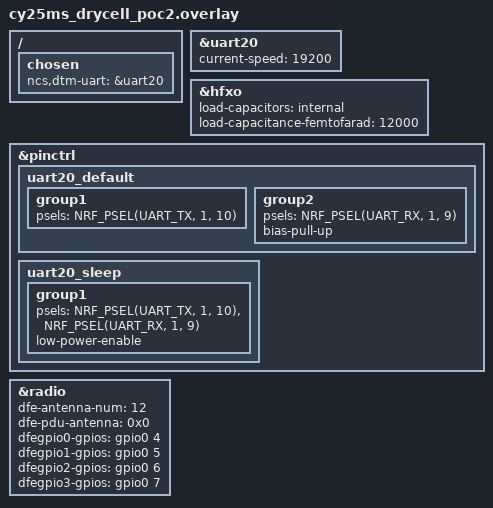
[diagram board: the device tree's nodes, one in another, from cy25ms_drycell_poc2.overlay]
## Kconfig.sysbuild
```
#
# Copyright (c) 2024 Nordic Semiconductor
#
# SPDX-License-Identifier: LicenseRef-Nordic-5-Clause
#

choice APPCORE
	default APPCORE_REMOTE_HCI if DTM_TRANSPORT_HCI
	default APPCORE_REMOTE_SHELL if SOC_NRF5340_CPUNET
	depends on SUPPORT_APPCORE

config APPCORE_REMOTE_HCI
	bool "remote_hci"
	depends on SOC_NRF5340_CPUNET
	help
	  Include remote_hci as the appcore image to use

endchoice

config APPCORE_IMAGE_NAME
	default "remote_hci" if APPCORE_REMOTE_HCI

config APPCORE_IMAGE_PATH
	default "${ZEPHYR_NRF_MODULE_DIR}/samples/bluetooth/direct_test_mode/remote_hci" if APPCORE_REMOTE_HCI

choice DTM_TRANSPORT
	default DTM_TRANSPORT_TWOWIRE
	prompt "Transport layer to use with DTM"
	help
	  Transport interface to use with the DTM.

config DTM_TRANSPORT_TWOWIRE
	bool "DTM over 2-wire UART"
	help
	  Use the 2-wire transport interface as the DTM transport layer.

config DTM_TRANSPORT_HCI
	bool "DTM over HCI UART [EXPERIMENTAL]"
	select EXPERIMENTAL
	help
	  Use the HCI UART transport interface as the DTM transport layer.

endchoice # DTM_TRANSPORT

config DTM_NO_DFE
	bool "Disable direction finding"
	help
	  Disable direction finding feature.

source "${ZEPHYR_BASE}/share/sysbuild/Kconfig"
```

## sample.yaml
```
sample:
  description: Bluetooth Low Energy Direct Test Mode sample
  name: Bluetooth LE Direct Test Mode
tests:
  sample.bluetooth.direct_test_mode:
    sysbuild: true
    build_only: true
    integration_platforms:
      - nrf5340dk/nrf5340/cpunet
      - nrf21540dk/nrf52840
      - nrf52840dk/nrf52840
      - nrf54l15dk/nrf54l05/cpuapp
      - nrf54l15dk/nrf54l10/cpuapp
      - nrf54l15dk/nrf54l15/cpuapp
      - nrf54h20dk/nrf54h20/cpurad
    platform_allow: nrf5340dk/nrf5340/cpunet nrf21540dk/nrf52840 nrf52840dk/nrf52840
                    nrf54l15dk/nrf54l05/cpuapp nrf54l15dk/nrf54l10/cpuapp
                    nrf54l15dk/nrf54l15/cpuapp nrf54h20dk/nrf54h20/cpurad
    tags: bluetooth ci_build sysbuild
  sample.bluetooth.direct_test_mode.hci:
    sysbuild: true
    build_only: true
    extra_args: FILE_SUFFIX=hci
    integration_platforms:
      - nrf5340dk/nrf5340/cpunet
      - nrf21540dk/nrf52840
      - nrf52840dk/nrf52840
      - nrf54l15dk/nrf54l15/cpuapp
      - nrf54h20dk/nrf54h20/cpurad
    platform_allow: nrf5340dk/nrf5340/cpunet nrf21540dk/nrf52840 nrf52840dk/nrf52840
                    nrf54l15dk/nrf54l15/cpuapp nrf54h20dk/nrf54h20/cpurad
    tags: bluetooth ci_build sysbuild
  sample.bluetooth.direct_test_mode.nrf5340_nrf21540:
    sysbuild: true
    build_only: true
    extra_args: SHIELD=nrf21540ek
    integration_platforms:
      - nrf5340dk/nrf5340/cpunet
    platform_allow: nrf5340dk/nrf5340/cpunet
    tags: bluetooth ci_build sysbuild
  sample.bluetooth.direct_test_mode.nrf5340_usb:
    sysbuild: true
    build_only: true
    extra_args: FILE_SUFFIX=usb
    integration_platforms:
      - nrf5340dk/nrf5340/cpunet
    platform_allow: nrf5340dk/nrf5340/cpunet
    tags: bluetooth ci_build sysbuild
  sample.bluetooth.direct_test_mode.nrf5340_nrf21540_usb:
    sysbuild: true
    build_only: true
    extra_args: SHIELD=nrf21540ek FILE_SUFFIX=usb
    integration_platforms:
      - nrf5340dk/nrf5340/cpunet
    platform_allow: nrf5340dk/nrf5340/cpunet
    tags: bluetooth ci_build sysbuild
  sample.bluetooth.direct_test_mode.nrf5340_nrf21540.no_automatic_power:
    sysbuild: true
    build_only: true
    extra_args: SHIELD=nrf21540ek
    extra_configs:
      - CONFIG_DTM_POWER_CONTROL_AUTOMATIC=n
    integration_platforms:
      - nrf5340dk/nrf5340/cpunet
    platform_allow: nrf5340dk/nrf5340/cpunet
    tags: bluetooth ci_build sysbuild
  sample.bluetooth.direct_test_mode.nrf5340_no_dfe:
    sysbuild: true
    build_only: true
    extra_args: DSB_CONFIG_DTM_NO_DFE=y
    integration_platforms:
      - nrf5340dk/nrf5340/cpunet
    platform_allow: nrf5340dk/nrf5340/cpunet
    tags: bluetooth ci_build sysbuild
```

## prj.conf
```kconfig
#
# Copyright (c) 2020 Nordic Semiconductor
#
# SPDX-License-Identifier: LicenseRef-Nordic-5-Clause
#

# Configure assertions
CONFIG_ASSERT=y
CONFIG_ASSERT_NO_COND_INFO=y
CONFIG_ASSERT_NO_MSG_INFO=y

CONFIG_HW_STACK_PROTECTION=y

CONFIG_CONSOLE=n
CONFIG_UART_CONSOLE=n

CONFIG_LOG=y
CONFIG_LOG_PRINTK=y
CONFIG_USE_SEGGER_RTT=y
CONFIG_LOG_BACKEND_RTT=y

# Use necessary peripherals
CONFIG_NRFX_TIMER0=y
CONFIG_NRFX_TIMER1=y
CONFIG_NRFX_TIMER2=y
CONFIG_CLOCK_CONTROL=y

CONFIG_FEM_AL_LIB=y
```

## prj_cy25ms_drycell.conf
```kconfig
#
# Copyright (c) 2020 Nordic Semiconductor
#
# SPDX-License-Identifier: LicenseRef-Nordic-5-Clause
#

# Configure assertions
CONFIG_ASSERT=y
CONFIG_ASSERT_NO_COND_INFO=y
CONFIG_ASSERT_NO_MSG_INFO=y

CONFIG_HW_STACK_PROTECTION=y

CONFIG_CONSOLE=n
CONFIG_UART_CONSOLE=n

CONFIG_LOG=y
CONFIG_LOG_PRINTK=y
CONFIG_USE_SEGGER_RTT=y
CONFIG_LOG_BACKEND_RTT=y

# Use necessary peripherals
CONFIG_NRFX_TIMER0=y
CONFIG_NRFX_TIMER1=y
CONFIG_NRFX_TIMER2=y

CONFIG_FEM_AL_LIB=y

# Disable the unsupported driver
CONFIG_NRFX_TIMER0=n
CONFIG_NRFX_TIMER1=n
CONFIG_NRFX_TIMER2=n

# Use necessary peripherals
CONFIG_NRFX_TIMER20=y
CONFIG_NRFX_TIMER10=y
CONFIG_NRFX_DPPI=y

#CONFIG_SOC_SERIES_NRF54LX=y

CONFIG_CLOCK_CONTROL_NRF_K32SRC_RC=y
CONFIG_CLOCK_CONTROL_NRF_K32SRC_XTAL=n
CONFIG_CLOCK_CONTROL_NRF_K32SRC_500PPM=y
```

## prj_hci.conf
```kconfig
#
# Copyright (c) 2020 Nordic Semiconductor
#
# SPDX-License-Identifier: LicenseRef-Nordic-5-Clause
#

# Configure assertions
CONFIG_ASSERT=y
CONFIG_ASSERT_NO_COND_INFO=y
CONFIG_ASSERT_NO_MSG_INFO=y

CONFIG_HW_STACK_PROTECTION=y

CONFIG_CONSOLE=n
CONFIG_UART_CONSOLE=n

CONFIG_LOG=y
CONFIG_LOG_PRINTK=y
CONFIG_USE_SEGGER_RTT=y
CONFIG_LOG_BACKEND_RTT=y

# Use necessary peripherals
CONFIG_NRFX_TIMER0=y
CONFIG_NRFX_TIMER1=y
CONFIG_NRFX_TIMER2=y
CONFIG_CLOCK_CONTROL=y

CONFIG_FEM_AL_LIB=y

CONFIG_DTM_TRANSPORT_HCI=y
CONFIG_NET_BUF=y
CONFIG_UART_ASYNC_API=y
```

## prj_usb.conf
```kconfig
#
# Copyright (c) 2020 Nordic Semiconductor
#
# SPDX-License-Identifier: LicenseRef-Nordic-5-Clause
#

# Configure assertions
CONFIG_ASSERT=y
CONFIG_ASSERT_NO_COND_INFO=y
CONFIG_ASSERT_NO_MSG_INFO=y

CONFIG_HW_STACK_PROTECTION=y

CONFIG_CONSOLE=n
CONFIG_UART_CONSOLE=n

CONFIG_LOG=y
CONFIG_LOG_PRINTK=y
CONFIG_USE_SEGGER_RTT=y
CONFIG_LOG_BACKEND_RTT=y

# Use necessary peripherals
CONFIG_NRFX_TIMER0=y
CONFIG_NRFX_TIMER1=y
CONFIG_NRFX_TIMER2=y
CONFIG_CLOCK_CONTROL=y

CONFIG_FEM_AL_LIB=y

CONFIG_DTM_USB=y
```

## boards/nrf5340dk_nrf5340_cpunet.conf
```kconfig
#
# Copyright (c) 2021 Nordic Semiconductor
#
# SPDX-License-Identifier: LicenseRef-Nordic-5-Clause
#

CONFIG_IPC_UART=y
CONFIG_IPC_SERVICE=y
CONFIG_IPC_SERVICE_BACKEND_RPMSG=y
CONFIG_MBOX=y

CONFIG_NRFX_GPPI=y

CONFIG_HEAP_MEM_POOL_SIZE=4096
```

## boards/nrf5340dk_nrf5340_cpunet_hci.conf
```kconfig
#
# Copyright (c) 2021 Nordic Semiconductor
#
# SPDX-License-Identifier: LicenseRef-Nordic-5-Clause
#

CONFIG_IPC_SERVICE=y
CONFIG_IPC_SERVICE_BACKEND_RPMSG=y
CONFIG_MBOX=y

CONFIG_NRFX_GPPI=y

CONFIG_HEAP_MEM_POOL_SIZE=4096

CONFIG_NRF_RPC=y
CONFIG_NRF_RPC_CBOR=y

CONFIG_NET_BUF=y
```

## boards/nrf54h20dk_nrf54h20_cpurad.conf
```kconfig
#
# Copyright (c) 2024 Nordic Semiconductor
#
# SPDX-License-Identifier: LicenseRef-Nordic-5-Clause
#

# Disable the unsupported driver
CONFIG_NRFX_TIMER0=n
CONFIG_NRFX_TIMER1=n
CONFIG_NRFX_TIMER2=n

# Use necessary peripherals
CONFIG_NRFX_TIMER020=y
CONFIG_NRFX_TIMER021=y
```

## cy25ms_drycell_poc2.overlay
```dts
/ {
	chosen {
		ncs,dtm-uart = &uart20;
	};
};
&uart20 {
	status = "okay";
	current-speed = <19200>;
	/delete-property/ hw-flow-control;
};

&hfxo {
	load-capacitors = "internal";
	load-capacitance-femtofarad = <12000>;
/*	load-capacitance-femtofarad = <8000>;
	load-capacitance-femtofarad = <12000>;
	load-capacitance-femtofarad = <14000>;
	load-capacitance-femtofarad = <15000>;
	load-capacitance-femtofarad = <16000>;
*/
};

&pinctrl {
	uart20_default: uart20_default {
		group1 {
			psels = <NRF_PSEL(UART_TX, 1, 10)>;
		};
		group2 {
			psels = <NRF_PSEL(UART_RX, 1, 9)>;
			bias-pull-up;
		};
	};

	uart20_sleep: uart20_sleep {
		group1 {
			psels = <NRF_PSEL(UART_TX, 1, 10)>,
					<NRF_PSEL(UART_RX, 1, 9)>;
			low-power-enable;
		};
	};
};

&radio {
	status = "okay";
	/* This is a number of antennas that are available on antenna matrix
	 * designed by Nordic. For more information see README.rst.
	 */
	dfe-antenna-num = <12>;
	/* This is a setting that enables antenna 12 (in antenna matrix designed
	 * by Nordic) for PDU. For more information see README.rst.
	 */
	dfe-pdu-antenna = <0x0>;

	/* These are GPIO pin numbers that are provided to
	 * Radio peripheral. The pins will be acquired by Radio to
	 * drive antenna switching.
	 * Pin numbers are selected to drive switches on antenna matrix
	 * desinged by Nordic. For more information see README.rst.
	 */
	dfegpio0-gpios = <&gpio0 4 0>;
	dfegpio1-gpios = <&gpio0 5 0>;
	dfegpio2-gpios = <&gpio0 6 0>;
	dfegpio3-gpios = <&gpio0 7 0>;
};
```

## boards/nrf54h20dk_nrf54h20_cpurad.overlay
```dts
/*
 * Copyright (c) 2024 Nordic Semiconductor ASA
 *
 * SPDX-License-Identifier: LicenseRef-Nordic-5-Clause
 */

 / {
	chosen {
		ncs,dtm-uart = &uart136;
	};
};

&uart135 {
	status = "disabled";
};

&uart136 {
	status = "okay";
	memory-regions = <&cpurad_dma_region>;
	current-speed = <19200>;
};

&dppic020 {
	status = "okay";
	source-channels = < 0 1 >;
	sink-channels = < 2 3 >;
};

&radio {
	status = "okay";
	/* This is a number of antennas that are available on antenna matrix
	 * designed by Nordic. For more information see README.rst.
	 */
	dfe-antenna-num = <12>;
	/* This is a setting that enables antenna 12 (in antenna matrix designed
	 * by Nordic) for PDU. For more information see README.rst.
	 */
	dfe-pdu-antenna = <0x0>;

	/* These are GPIO pin numbers that are provided to
	 * Radio peripheral. The pins will be acquired by Radio to
	 * drive antenna switching.
	 * Pin numbers are selected to drive switches on antenna matrix
	 * desinged by Nordic. For more information see README.rst.
	 */
	dfegpio0-gpios = <&gpio0 4 0>;
	dfegpio1-gpios = <&gpio0 5 0>;
	dfegpio2-gpios = <&gpio0 6 0>;
	dfegpio3-gpios = <&gpio0 7 0>;
};
```

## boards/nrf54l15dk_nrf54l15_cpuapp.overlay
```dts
/*
 * Copyright (c) 2024 Nordic Semiconductor ASA
 *
 * SPDX-License-Identifier: LicenseRef-Nordic-5-Clause
 */

 / {
	chosen {
		ncs,dtm-uart = &uart00;
	};
};
/*&uart20 {
	status = "disabled";
};
*/
&spi00 {
    status = "disabled";
};

&pinctrl{
    uart00_default: uart00_default {
        group1 {
            psels = <NRF_PSEL(UART_TX, 2, 2)>;
        };
        group2 {
            psels = <NRF_PSEL(UART_RX, 2, 0)>;
            bias-pull-up;
        };
    };
   
    uart00_sleep: uart00_sleep {
     group1 {
        psels = <NRF_PSEL(UART_TX, 2, 2)>,
                <NRF_PSEL(UART_RX, 2, 0)>;
        low-power-enable;
     };
    };
};
&uart00 {
    status = "okay";
    current-speed = <19200>;
    pinctrl-0 = <&uart00_default>;
    pinctrl-1 = <&uart00_sleep>;
    pinctrl-names = "default", "sleep";

	/delete-property/ hw-flow-control;
};

&radio {
	status = "okay";
	/* This is a number of antennas that are available on antenna matrix
	 * designed by Nordic. For more information see README.rst.
	 */
	dfe-antenna-num = <12>;
	/* This is a setting that enables antenna 12 (in antenna matrix designed
	 * by Nordic) for PDU. For more information see README.rst.
	 */
	dfe-pdu-antenna = <0x0>;

	/* These are GPIO pin numbers that are provided to
	 * Radio peripheral. The pins will be acquired by Radio to
	 * drive antenna switching.
	 * Pin numbers are selected to drive switches on antenna matrix
	 * desinged by Nordic. For more information see README.rst.
	 */
	dfegpio0-gpios = <&gpio0 4 0>;
	dfegpio1-gpios = <&gpio0 5 0>;
	dfegpio2-gpios = <&gpio0 6 0>;
	dfegpio3-gpios = <&gpio0 7 0>;
};
```

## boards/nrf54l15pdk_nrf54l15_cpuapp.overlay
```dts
/*
 * Copyright (c) 2023 Nordic Semiconductor ASA
 *
 * SPDX-License-Identifier: LicenseRef-Nordic-5-Clause
 */

/ {
	chosen {
		ncs,dtm-uart = &uart20;
	};
};

&uart20 {
	status = "okay";
	current-speed = <19200>;
};

&radio {
	status = "okay";
	/* This is a number of antennas that are available on antenna matrix
	 * designed by Nordic. For more information see README.rst.
	 */
	dfe-antenna-num = <12>;
	/* This is a setting that enables antenna 12 (in antenna matrix designed
	 * by Nordic) for PDU. For more information see README.rst.
	 */
	dfe-pdu-antenna = <0x0>;

	/* These are GPIO pin numbers that are provided to
	 * Radio peripheral. The pins will be acquired by Radio to
	 * drive antenna switching.
	 * Pin numbers are selected to drive switches on antenna matrix
	 * desinged by Nordic. For more information see README.rst.
	 */
	dfegpio0-gpios = <&gpio0 4 0>;
	dfegpio1-gpios = <&gpio0 5 0>;
	dfegpio2-gpios = <&gpio0 6 0>;
	dfegpio3-gpios = <&gpio0 7 0>;
};
```

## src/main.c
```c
/*
 * Copyright (c) 2020 Nordic Semiconductor ASA
 *
 * SPDX-License-Identifier: LicenseRef-Nordic-5-Clause
 */

#include <zephyr/device.h>
#include <zephyr/sys/printk.h>

#include "transport/dtm_transport.h"

int main(void)
{
	int err;
	union dtm_tr_packet cmd;

	printk("Starting Direct Test Mode example\n");

	err = dtm_tr_init();
	if (err) {
		printk("Error initializing DTM transport: %d\n", err);
		return err;
	}

	for (;;) {
		cmd = dtm_tr_get();
		err = dtm_tr_process(cmd);
		if (err) {
			printk("Error processing command: %d\n", err);
			return err;
		}
	}
}
```

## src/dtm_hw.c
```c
/*
 * Copyright (c) 2020 Nordic Semiconductor ASA
 *
 * SPDX-License-Identifier: LicenseRef-Nordic-5-Clause
 */

#include "nrf.h"

#include "dtm_hw.h"
#include "dtm_hw_config.h"

/* All valid power levels (in dBm) supported by the SoC. */
const int8_t nrf_power_value[] = {
#if defined(RADIO_TXPOWER_TXPOWER_Neg100dBm)
	-100,
#endif /* defined(RADIO_TXPOWER_TXPOWER_Neg100dBm) */
#if defined(RADIO_TXPOWER_TXPOWER_Neg70dBm)
	-70,
#endif /* defined(RADIO_TXPOWER_TXPOWER_Neg70dBm) */
#if defined(RADIO_TXPOWER_TXPOWER_Neg46dBm)
	-46,
#endif /* defined(RADIO_TXPOWER_TXPOWER_Neg46dBm) */
#if defined(RADIO_TXPOWER_TXPOWER_Neg40dBm)
	-40,
#endif /* RADIO_TXPOWER_TXPOWER_Neg40dBm */
#if defined(RADIO_TXPOWER_TXPOWER_Neg30dBm)
	-30,
#endif /* defined(RADIO_TXPOWER_TXPOWER_Neg30dBm) */
#if defined(RADIO_TXPOWER_TXPOWER_Neg28dBm)
	-28,
#endif /* defined(RADIO_TXPOWER_TXPOWER_Neg28dBm) */
#if defined(RADIO_TXPOWER_TXPOWER_Neg22dBm)
	-22,
#endif /* defined(RADIO_TXPOWER_TXPOWER_Neg22dBm) */
	-20,
#if defined(RADIO_TXPOWER_TXPOWER_Neg18dBm)
	-18,
#endif /* defined(RADIO_TXPOWER_TXPOWER_Neg18dBm) */
	-16,
#if defined(RADIO_TXPOWER_TXPOWER_Neg14dBm)
	-14,
#endif /* defined(RADIO_TXPOWER_TXPOWER_Neg14dBm) */
	-12,
#if defined(RADIO_TXPOWER_TXPOWER_Neg10dBm)
	-10,
#endif /* defined(RADIO_TXPOWER_TXPOWER_Neg10dBm) */
#if defined(RADIO_TXPOWER_TXPOWER_Neg9dBm)
	-9,
#endif /* defined(RADIO_TXPOWER_TXPOWER_Neg9dBm) */
	-8,
#if defined(RADIO_TXPOWER_TXPOWER_Neg7dBm)
	-7,
#endif /* defined(RADIO_TXPOWER_TXPOWER_Neg7dBm) */
#if defined(RADIO_TXPOWER_TXPOWER_Neg6dBm)
	-6,
#endif /* defined(RADIO_TXPOWER_TXPOWER_Neg6dBm) */
#if defined(RADIO_TXPOWER_TXPOWER_Neg5dBm)
	-5,
#endif /* defined(RADIO_TXPOWER_TXPOWER_Neg5dBm) */
	-4,
#if defined(RADIO_TXPOWER_TXPOWER_Neg3dBm)
	-3,
#endif /* defined (RADIO_TXPOWER_TXPOWER_Neg3dBm) */
#if defined(RADIO_TXPOWER_TXPOWER_Neg2dBm)
	-2,
#endif /* defined (RADIO_TXPOWER_TXPOWER_Neg2dBm) */
#if defined(RADIO_TXPOWER_TXPOWER_Neg1dBm)
	-1,
#endif /* defined (RADIO_TXPOWER_TXPOWER_Neg1dBm) */
	0,
#if defined(RADIO_TXPOWER_TXPOWER_Pos1dBm)
	1,
#endif /* RADIO_TXPOWER_TXPOWER_Pos1dBm */
#if defined(RADIO_TXPOWER_TXPOWER_Pos2dBm)
	2,
#endif /* defined(RADIO_TXPOWER_TXPOWER_Pos2dBm) */
#if defined(RADIO_TXPOWER_TXPOWER_Pos3dBm)
	3,
#endif /* defined(RADIO_TXPOWER_TXPOWER_Pos3dBm) */
#if defined(RADIO_TXPOWER_TXPOWER_Pos4dBm)
	4,
#endif /* defined(RADIO_TXPOWER_TXPOWER_Pos4dBm) */
#if defined(RADIO_TXPOWER_TXPOWER_Pos5dBm)
	5,
#endif /* defined(RADIO_TXPOWER_TXPOWER_Pos5dBm) */
#if defined(RADIO_TXPOWER_TXPOWER_Pos6dBm)
	6,
#endif /* defined(RADIO_TXPOWER_TXPOWER_Pos6dBm) */
#if defined(RADIO_TXPOWER_TXPOWER_Pos7dBm)
	7,
#endif /* defined(RADIO_TXPOWER_TXPOWER_Pos7dBm) */
#if defined(RADIO_TXPOWER_TXPOWER_Pos8dBm)
	8,
#endif /* defined(RADIO_TXPOWER_TXPOWER_Pos8dBm) */
#if defined(RADIO_TXPOWER_TXPOWER_Pos9dBm)
	9,
#endif /* defined(RADIO_TXPOWER_TXPOWER_Pos9dBm) */
#if defined(RADIO_TXPOWER_TXPOWER_Pos10dBm)
	10
#endif /* defined(RADIO_TXPOWER_TXPOWER_Pos10dBm) */
};

#if DIRECTION_FINDING_SUPPORTED

#define DTM_MAX_ANTENNA_NUMBER 19

#define DFE_GPIO_PIN_DISCONNECT (RADIO_PSEL_DFEGPIO_CONNECT_Disconnected << \
				 RADIO_PSEL_DFEGPIO_CONNECT_Pos)

#define HAS_DFE_GPIO(idx) DT_NODE_HAS_PROP(RADIO_NODE, dfegpio##idx##_gpios)

/* Run a macro 'fn' on each available DFE GPIO index, from 0 to
 * MAX_DFE_GPIO-1, with the given parenthesized separator.
 */
#define FOR_EACH_DFE_GPIO(fn, sep) \
	FOR_EACH(fn, sep, 0, 1, 2, 3, 4, 5, 6, 7)

/* The number of dfegpio[n]-gpios properties which are set. */
#define DFE_GPIO_NUM (FOR_EACH_DFE_GPIO(HAS_DFE_GPIO, (+)))

#define PDU_ANTENNA DT_PROP(RADIO_NODE, dfe_pdu_antenna)

/* The minimum number of antennas required to enable antenna switching. */
#define MIN_ANTENNA_NUM 1

/* The maximum number of antennas supported by the number of
 * dfegpio[n]-gpios properties which are set.
 */
#if (DFE_GPIO_NUM > 0)
#define MAX_ANTENNA_NUM BIT(DFE_GPIO_NUM)
#else
#define MAX_ANTENNA_NUM 0
#endif

/*
 * Check that the number of antennas has been set, and that enough
 * pins are configured to represent each pattern for the given number
 * of antennas.
 */
#define HAS_ANTENNA_NUM DT_NODE_HAS_PROP(RADIO_NODE, dfe_antenna_num)

BUILD_ASSERT(HAS_ANTENNA_NUM,
	     "You must set the dfe-antenna-num property in the radio node "
	     "to enable antenna switching.");

#define ANTENNA_NUM DT_PROP_OR(RADIO_NODE, dfe_antenna_num, 0)


BUILD_ASSERT(!HAS_ANTENNA_NUM || (ANTENNA_NUM <= MAX_ANTENNA_NUM),
	     "Insufficient number of GPIO pins configured. "
	     "Set more dfegpio[n]-gpios properties.");
BUILD_ASSERT(!HAS_ANTENNA_NUM || (ANTENNA_NUM >= MIN_ANTENNA_NUM),
	     "Insufficient number of antennas provided. "
	     "Increase the dfe-antenna-num property.");

#define HAS_PDU_ANTENNA DT_NODE_HAS_PROP(RADIO_NODE, dfe_pdu_antenna)

BUILD_ASSERT(HAS_PDU_ANTENNA,
	     "Missing antenna pattern used to select antenna for PDU Tx "
	     "during the CTE Idle state. "
	     "Set the dfe-pdu-antenna devicetree property.");

/*
 * Check that each dfegpio[n]-gpios property has a zero flags cell.
 */
#define ASSERT_DFE_GPIO_FLAGS_ARE_ZERO(idx)				   \
	BUILD_ASSERT(DT_GPIO_FLAGS(RADIO_NODE, dfegpio##idx##_gpios) == 0, \
		     "The flags cell in each dfegpio[n]-gpios "		   \
		     "property must be zero.")

FOR_EACH_DFE_GPIO(ASSERT_DFE_GPIO_FLAGS_ARE_ZERO, (;));

#define DFE_GPIO_PSEL(idx)					  \
	NRF_DT_GPIOS_TO_PSEL_OR(RADIO_NODE, dfegpio##idx##_gpios, \
				DTM_HW_DFE_PSEL_NOT_SET)

static const struct dtm_ant_cfg {
	uint8_t ant_num;
	/* Selection of GPIOs to be used to switch antennas by Radio */
	uint8_t dfe_gpio[DTM_HW_MAX_DFE_GPIO];
} ant_cfg = {
	.ant_num = (ANTENNA_NUM > DTM_MAX_ANTENNA_NUMBER) ? DTM_MAX_ANTENNA_NUMBER : ANTENNA_NUM,
	.dfe_gpio = { FOR_EACH_DFE_GPIO(DFE_GPIO_PSEL, (,)) }
};
#endif /* DIRECTION_FINDING_SUPPORTED */

bool dtm_hw_radio_validate(int8_t tx_power,
			   nrf_radio_mode_t radio_mode)
{
	/* Initializing code below is quite generic - for BLE, the values are
	 * fixed, and expressions are constant. Non-constant values are
	 * essentially set in radio_prepare().
	 */

	if (!(
#if CONFIG_HAS_HW_NRF_RADIO_BLE_CODED
		radio_mode == NRF_RADIO_MODE_BLE_LR125KBIT  ||
		radio_mode == NRF_RADIO_MODE_BLE_LR500KBIT  ||
#endif /* CONFIG_HAS_HW_NRF_RADIO_BLE_CODED */
		radio_mode == NRF_RADIO_MODE_BLE_1MBIT      ||
		radio_mode == NRF_RADIO_MODE_BLE_2MBIT
		)
	) {
		return false;
	}

	for (size_t i = 0; i < ARRAY_SIZE(nrf_power_value); i++) {
		if (tx_power == nrf_power_value[i]) {
			return true;
		}
	}

	return false;
}

bool dtm_hw_radio_lr_check(nrf_radio_mode_t radio_mode)
{
#if CONFIG_HAS_HW_NRF_RADIO_BLE_CODED
	if (radio_mode == NRF_RADIO_MODE_BLE_LR125KBIT) {
		return true;
	}

	if (radio_mode == NRF_RADIO_MODE_BLE_LR500KBIT) {
		return true;
	}
#endif /* CONFIG_HAS_HW_NRF_RADIO_BLE_CODED */

	return false;
}

uint32_t dtm_hw_radio_min_power_get(void)
{
	return nrf_power_value[0];
}

uint32_t dtm_hw_radio_max_power_get(void)
{
	return nrf_power_value[ARRAY_SIZE(nrf_power_value) - 1];
}

size_t dtm_hw_radio_power_array_size_get(void)
{
	return ARRAY_SIZE(nrf_power_value);
}

const int8_t *dtm_hw_radio_power_array_get(void)
{
	return nrf_power_value;
}

#if DIRECTION_FINDING_SUPPORTED
size_t dtm_hw_radio_antenna_number_get(void)
{
	return ant_cfg.ant_num;
}

const uint8_t *dtm_hw_radio_antenna_pin_array_get(void)
{
	return ant_cfg.dfe_gpio;
}

uint8_t dtm_hw_radio_pdu_antenna_get(void)
{
	return PDU_ANTENNA;
}
#endif /* DIRECTION_FINDING_SUPPORTED */
```

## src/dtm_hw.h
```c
/*
 * Copyright (c) 2020 Nordic Semiconductor ASA
 *
 * SPDX-License-Identifier: LicenseRef-Nordic-5-Clause
 */

#ifndef DTM_HW_H_
#define DTM_HW_H_

#include <stdbool.h>
#include <zephyr/types.h>

#include <hal/nrf_radio.h>

#ifdef __cplusplus
extern "C" {
#endif

/* Number of PSEL_DFEGPIO[n] registers in the radio peripheral. */
#define DTM_HW_MAX_DFE_GPIO 8

/* Indicates that GPIO pin is not connected to the radio */
#define DTM_HW_DFE_PSEL_NOT_SET 0xFF

/* Disconnect pin from the RADIO DFGPIO register. */
#define DTM_HW_DFE_GPIO_PIN_DISCONNECT (RADIO_PSEL_DFEGPIO_CONNECT_Disconnected << \
					RADIO_PSEL_DFEGPIO_CONNECT_Pos)

/**@brief Function for validating tx power and radio mode settings.
 * @param[in] tx_power    TX power for transmission test in dBm.
 * @param[in] radio_mode  Radio mode value.
 *
 * @retval true  If validation was successful
 * @retval false Otherwise
 */
bool dtm_hw_radio_validate(int8_t tx_power,
			   nrf_radio_mode_t radio_mode);

/**@brief Function for checking if Radio operates in Long Range mode.
 * @param[in] radio_mode  Radio mode value.
 *
 * @retval true  If Long Range Radio mode is set
 * @retval false Otherwise
 */
bool dtm_hw_radio_lr_check(nrf_radio_mode_t radio_mode);

/**@brief Function for getting minimum tx power.
 *
 * @retval Minimum tx power value.
 */
uint32_t dtm_hw_radio_min_power_get(void);

/**@brief Function for getting maximum tx power.
 *
 * @retval Maximum tx power value.
 */
uint32_t dtm_hw_radio_max_power_get(void);

/**@brief Function for getting power array size. This array contains all
 *        possible tx power values for given divice sorted in ascending
 *        order.
 *
 * @reval Size of the tx power array.
 */
size_t dtm_hw_radio_power_array_size_get(void);

/**@brief Function for getting tx power array. This array contains all
 *        possible tx power values for given divice sorted in ascending
 *        order.
 *
 * @retval Size of the tx power array.
 */
const int8_t *dtm_hw_radio_power_array_get(void);

/**@brief Function for getting antenna pins array. This array contains
 *        all antenna pins data.
 *
 * @retval Pointer to the first element in antenna pins array.
 */
const uint8_t *dtm_hw_radio_antenna_pin_array_get(void);

/**@brief Function for getting available antenna number.
 *
 * @retval Maximum antenna number that DTM can use.
 */
size_t dtm_hw_radio_antenna_number_get(void);

/**@brief Function for getting the PDU antenna.
 *
 * @retval The PDU antenna.
 */
uint8_t dtm_hw_radio_pdu_antenna_get(void);

#ifdef __cplusplus
}
#endif

#endif /* DTM_HW_H_ */
```
